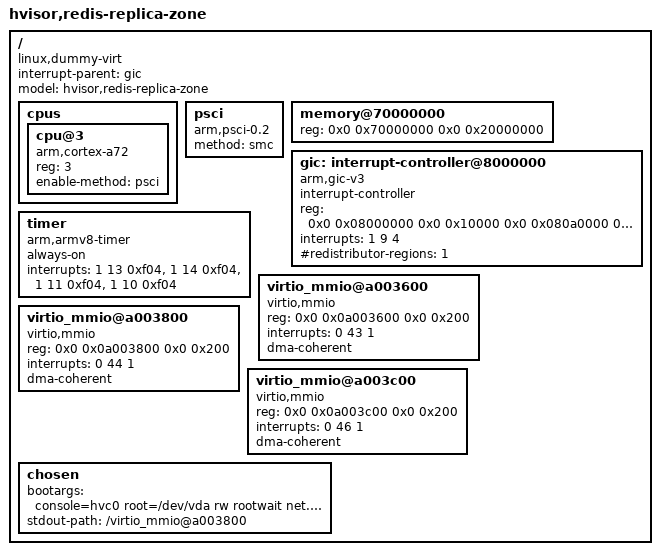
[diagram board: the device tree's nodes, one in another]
/dts-v1/;

/ {
	#address-cells = <2>;
	#size-cells = <2>;
	interrupt-parent = <&gic>;
	model = "hvisor,redis-replica-zone";
	compatible = "linux,dummy-virt";

	cpus {
		#address-cells = <1>;
		#size-cells = <0>;

		cpu@3 {
			device_type = "cpu";
			compatible = "arm,cortex-a72";
			reg = <3>;
			enable-method = "psci";
		};
	};

	psci {
		compatible = "arm,psci-0.2";
		method = "smc";
	};

	memory@70000000 {
		device_type = "memory";
		reg = <0x0 0x70000000 0x0 0x20000000>;
	};

	gic: interrupt-controller@8000000 {
		compatible = "arm,gic-v3";
		#interrupt-cells = <3>;
		interrupt-controller;
		#address-cells = <2>;
		#size-cells = <2>;
		ranges;
		reg = <0x0 0x08000000 0x0 0x10000
		       0x0 0x080a0000 0x0 0xf60000>;
		interrupts = <1 9 4>;
		#redistributor-regions = <1>;
	};

	timer {
		compatible = "arm,armv8-timer", "arm,armv7-timer";
		always-on;
		interrupts = <1 13 0xf04>,
		             <1 14 0xf04>,
		             <1 11 0xf04>,
		             <1 10 0xf04>;
	};

	virtio_mmio@a003600 {
		compatible = "virtio,mmio";
		reg = <0x0 0x0a003600 0x0 0x200>;
		interrupts = <0 43 1>;
		dma-coherent;
	};

	virtio_mmio@a003800 {
		compatible = "virtio,mmio";
		reg = <0x0 0x0a003800 0x0 0x200>;
		interrupts = <0 44 1>;
		dma-coherent;
	};

	virtio_mmio@a003c00 {
		compatible = "virtio,mmio";
		reg = <0x0 0x0a003c00 0x0 0x200>;
		interrupts = <0 46 1>;
		dma-coherent;
	};

	chosen {
		bootargs = "console=hvc0 root=/dev/vda rw rootwait net.ifnames=0 init=/usr/local/sbin/redis-eval-init";
		stdout-path = "/virtio_mmio@a003800";
	};
};
